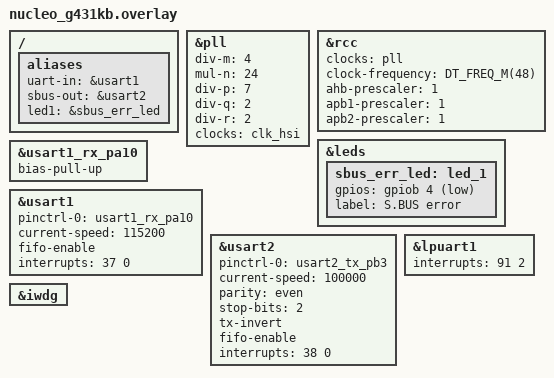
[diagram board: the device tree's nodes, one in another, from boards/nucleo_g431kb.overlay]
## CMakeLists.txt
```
# SPDX-License-Identifier: Apache-2.0

cmake_minimum_required(VERSION 3.28.0)

find_package(Zephyr REQUIRED HINTS $ENV{ZEPHYR_BASE})
project(uart_sbus)

target_sources(app PRIVATE src/main.c src/sbus_pipe.c)
```

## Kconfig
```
# SPDX-License-Identifier: Apache-2.0

mainmenu "UART to S.BUS converter"

source "Kconfig.zephyr"

config UART_SBUS_SBUS2
	bool "Accept S.BUS2 slot footers"
	default n
	help
	  Valid footer iff (byte & mask) == 0x00.
	  n: mask 0xFF (classic S.BUS, footer 0x00 only).
	  y: mask 0xCB (ignore bits 2,4,5: 0x00/0x04/0x14/0x24/0x34).
```

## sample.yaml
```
sample:
  name: UART to S.BUS converter
tests:
  sample.uart_sbus:
    platform_allow:
      - nucleo_g431kb
      - sbus_bridge
    integration_platforms:
      - nucleo_g431kb
      - sbus_bridge
    build_only: true
    tags:
      - uart
      - sbus
```

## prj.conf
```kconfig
CONFIG_SERIAL=y
CONFIG_UART_INTERRUPT_DRIVEN=y
CONFIG_CONSOLE=y
CONFIG_GPIO=y
CONFIG_WATCHDOG=y
CONFIG_RESET_ON_FATAL_ERROR=y
CONFIG_STACK_SENTINEL=y
CONFIG_FAULT_DUMP=1
CONFIG_ISR_STACK_SIZE=1024
CONFIG_MAIN_STACK_SIZE=1024
```

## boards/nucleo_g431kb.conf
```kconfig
CONFIG_UART_CONSOLE=y
# Board defconfig enables MPU stack guards; prefer software sentinel (prj.conf).
CONFIG_HW_STACK_PROTECTION=n
```

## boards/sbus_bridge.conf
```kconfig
# SPDX-License-Identifier: MIT

CONFIG_RTT_CONSOLE=y
CONFIG_USE_SEGGER_RTT=y
```

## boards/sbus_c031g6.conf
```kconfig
# SPDX-License-Identifier: Apache-2.0

# prj.conf enables UART_CONSOLE; this board has no spare USART for VCP.
CONFIG_UART_CONSOLE=n
CONFIG_RTT_CONSOLE=y
CONFIG_USE_SEGGER_RTT=y
```

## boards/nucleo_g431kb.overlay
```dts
/*
 * SPDX-License-Identifier: Apache-2.0
 *
 * NUCLEO-G431KB (UM2397) Arduino Nano mapping, not Nucleo-64:
 *   ST-Link VCP is LPUART1 PA2/PA3 (not D0/D1).
 *   UART in:  USART1 RX PA10 = D0 (CN4 pin 2).
 *   S.BUS:    USART2 TX PB3  = D13 (CN3 pin 15).
 *   Error LED: GPIOB 4 = D12 (CN4 pin 15), open-drain active-low to 5 V.
 * D7 is PF0 (OSC_IN) and D3 is PB0; neither is a USART pin.
 * Default SB2 routes PB7 to A4, not to D4, so USART1_RX_PB7 is a trap.
 * Do not use A7 (PA2): LPUART1 TX / ST-Link VCP, not 5 V-tolerant.
 */

#include <zephyr/dt-bindings/gpio/gpio.h>

/ {
	aliases {
		uart-in = &usart1;
		sbus-out = &usart2;
		led1 = &sbus_err_led;
	};
};

/*
 * Match sbus_bridge (STM32C031) at 48 MHz SYSCLK.
 * G4 HSI is 16 MHz, so PLL is required: 16/4*24/2 = 48.
 */
&pll {
	div-m = <4>;
	mul-n = <24>;
	div-p = <7>;
	div-q = <2>;
	div-r = <2>;
	clocks = <&clk_hsi>;
	status = "okay";
};

&rcc {
	clocks = <&pll>;
	clock-frequency = <DT_FREQ_M(48)>;
	ahb-prescaler = <1>;
	apb1-prescaler = <1>;
	apb2-prescaler = <1>;
};

&leds {
	sbus_err_led: led_1 {
		gpios = <&gpiob 4 (GPIO_OPEN_DRAIN | GPIO_ACTIVE_LOW)>;
		label = "S.BUS error";
	};
};

&usart1_rx_pa10 {
	bias-pull-up;
};

&usart1 {
	pinctrl-0 = <&usart1_rx_pa10>;
	pinctrl-names = "default";
	current-speed = <115200>;
	fifo-enable;
	interrupts = <37 0>;
	status = "okay";
};

&usart2 {
	pinctrl-0 = <&usart2_tx_pb3>;
	pinctrl-names = "default";
	current-speed = <100000>;
	parity = "even";
	stop-bits = "2";
	tx-invert;
	fifo-enable;
	interrupts = <38 0>;
	status = "okay";
};

&lpuart1 {
	interrupts = <91 2>;
};

&iwdg {
	status = "okay";
};
```

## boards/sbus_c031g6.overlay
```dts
/*
 * SPDX-License-Identifier: Apache-2.0
 *
 * Aliases, LEDs, and USART line coding live in the sbus_c031g6 board DTS.
 * This overlay is kept so the sample has an explicit board file; the
 * duplicate aliases match the board and are harmless.
 */

/ {
	aliases {
		uart-in = &usart1;
		sbus-out = &usart2;
		led0 = &led_green;
		led1 = &led_red;
	};
};
```

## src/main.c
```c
/*
 * SPDX-License-Identifier: Apache-2.0
 */

#include <zephyr/device.h>
#include <zephyr/drivers/gpio.h>
#include <zephyr/drivers/uart.h>
#include <zephyr/drivers/watchdog.h>
#include <zephyr/kernel.h>
#include <zephyr/sys/atomic.h>
#include <zephyr/sys/clock.h>
#include <zephyr/sys/printk.h>
#include <zephyr/sys/util.h>

#include "sbus_pipe.h"

#define UART_IN_NODE     DT_ALIAS(uart_in)
#define SBUS_OUT_NODE    DT_ALIAS(sbus_out)
#define LED_GREEN_NODE   DT_ALIAS(led0)
#define LED_RED_NODE     DT_ALIAS(led1)
#define WDT_NODE         DT_ALIAS(watchdog0)

#define MAIN_TICK_MS       5
#define WDT_WINDOW_MS      50
#define GREEN_PULSE_MS     50
#define RED_SUPERSEDE_MS   200
#define RED_FAULT_MS       2000
#define STATS_PERIOD_MS    1000
#define FRAME_LED_DIVISOR  10

BUILD_ASSERT(DT_NODE_EXISTS(UART_IN_NODE), "alias uart-in missing");
BUILD_ASSERT(DT_NODE_EXISTS(SBUS_OUT_NODE), "alias sbus-out missing");
BUILD_ASSERT(DT_NODE_EXISTS(LED_GREEN_NODE), "alias led0 missing");
BUILD_ASSERT(DT_NODE_EXISTS(LED_RED_NODE), "alias led1 missing");
BUILD_ASSERT(DT_NODE_EXISTS(WDT_NODE), "alias watchdog0 missing");
BUILD_ASSERT(DT_IRQ(UART_IN_NODE, priority) == DT_IRQ(SBUS_OUT_NODE, priority),
	     "uart-in and sbus-out must share NVIC priority");

static const struct device *const uart_in = DEVICE_DT_GET(UART_IN_NODE);
static const struct device *const sbus_out = DEVICE_DT_GET(SBUS_OUT_NODE);
static const struct device *const wdt = DEVICE_DT_GET(WDT_NODE);
static const struct gpio_dt_spec led_green = GPIO_DT_SPEC_GET(LED_GREEN_NODE, gpios);
static const struct gpio_dt_spec led_red = GPIO_DT_SPEC_GET(LED_RED_NODE, gpios);

static struct sbus_pipe pipe;
K_SEM_DEFINE(wake, 0, 1);

static void uart_in_cb(const struct device *dev, void *user_data)
{
	uint8_t c;
	int err;

	ARG_UNUSED(user_data);

	uart_irq_update(dev);

	err = uart_err_check(dev);
	if (err != 0) {
		atomic_inc(&pipe.rx_err);
		k_sem_give(&wake);
	}

	while (uart_irq_rx_ready(dev) > 0) {
		if (uart_fifo_read(dev, &c, 1) < 1) {
			break;
		}
		if (sbus_pipe_push(&pipe, c)) {
			uart_irq_tx_enable(sbus_out);
			if (pipe.collect == NULL) {
				k_sem_give(&wake);
			}
		}
	}
}

static void sbus_out_cb(const struct device *dev, void *user_data)
{
	uint8_t c;

	ARG_UNUSED(user_data);

	uart_irq_update(dev);

	while (uart_irq_tx_ready(dev) > 0) {
		if (!sbus_pipe_pop(&pipe, &c)) {
			uart_irq_tx_disable(dev);
			break;
		}
		k_sem_give(&wake);
		if (uart_fifo_fill(dev, &c, 1) < 1) {
			uart_irq_tx_disable(dev);
			break;
		}
	}
}

static uint16_t remaining_sub(uint16_t remaining, uint16_t dt)
{
	return remaining > dt ? remaining - dt : 0;
}

int main(void)
{
	uint32_t tx_frames_prev = 0;
	uint32_t tx_frames_snap = 0;
	uint32_t supersede_snap = 0;
	uint32_t sync_err_snap = 0;
	uint32_t rx_err_snap = 0;
	uint16_t green_ms = 0;
	uint16_t red_ms = 0;
	int64_t last_led = k_uptime_get();
	int64_t last_stats = last_led;
	int wdt_channel;
	struct wdt_timeout_cfg wdt_cfg = {
		.flags = WDT_FLAG_RESET_SOC,
		.window.min = 0,
		.window.max = WDT_WINDOW_MS,
	};

	sbus_pipe_init(&pipe);

	if (!device_is_ready(uart_in) || !device_is_ready(sbus_out)) {
		printk("sbus: UART device not ready\n");
		return 0;
	}
	if (!gpio_is_ready_dt(&led_green) || !gpio_is_ready_dt(&led_red)) {
		printk("sbus: LED GPIO not ready\n");
		return 0;
	}
	if (gpio_pin_configure_dt(&led_green, GPIO_OUTPUT_INACTIVE) < 0 ||
	    gpio_pin_configure_dt(&led_red, GPIO_OUTPUT_INACTIVE) < 0) {
		printk("sbus: LED configure failed\n");
		return 0;
	}
	if (!device_is_ready(wdt)) {
		printk("sbus: watchdog not ready\n");
		return 0;
	}
	wdt_channel = wdt_install_timeout(wdt, &wdt_cfg);
	if (wdt_channel < 0) {
		printk("sbus: watchdog install failed\n");
		return 0;
	}
	if (wdt_setup(wdt, WDT_OPT_PAUSE_HALTED_BY_DBG) < 0) {
		printk("sbus: watchdog setup failed\n");
		return 0;
	}

	uart_irq_callback_user_data_set(uart_in, uart_in_cb, NULL);
	uart_irq_callback_user_data_set(sbus_out, sbus_out_cb, NULL);
	uart_irq_err_enable(uart_in);
	uart_irq_rx_enable(uart_in);

#if defined(CONFIG_BOARD_SBUS_BRIDGE)
	printk("sbus: PA1 115200 8N1 -> PA4 S.BUS 100k 8E2\n");
#elif defined(CONFIG_BOARD_NUCLEO_G431KB)
	printk("sbus: D0/PA10 115200 8N1 -> D13/PB3 S.BUS 100k 8E2\n");
#else
	printk("sbus: 115200 8N1 -> S.BUS 100k 8E2\n");
#endif

	for (;;) {
		int64_t now;
		uint16_t dt;
		uint32_t rx;
		uint32_t tx;
		uint32_t err;
		uint32_t frames;
		uint32_t sup;
		uint32_t sync;
		uint32_t tx_frames;

		k_sem_take(&wake, K_MSEC(MAIN_TICK_MS));
		wdt_feed(wdt, wdt_channel);
		now = k_uptime_get();
		dt = (uint16_t)CLAMP(now - last_led, 0, 1000);
		last_led = now;

		green_ms = remaining_sub(green_ms, dt);
		red_ms = remaining_sub(red_ms, dt);

		tx_frames = (uint32_t)atomic_get(&pipe.tx_frames);
		if ((tx_frames / FRAME_LED_DIVISOR) != (tx_frames_snap / FRAME_LED_DIVISOR)) {
			green_ms = MAX(green_ms, GREEN_PULSE_MS);
		}
		tx_frames_snap = tx_frames;

		sup = (uint32_t)atomic_get(&pipe.supersede);
		if (sup != supersede_snap) {
			red_ms = MAX(red_ms, RED_SUPERSEDE_MS);
		}
		supersede_snap = sup;

		sync = (uint32_t)atomic_get(&pipe.sync_err);
		err = (uint32_t)atomic_get(&pipe.rx_err);
		if (sync != sync_err_snap || err != rx_err_snap) {
			red_ms = MAX(red_ms, RED_FAULT_MS);
		}
		sync_err_snap = sync;
		rx_err_snap = err;

		if (green_ms > 0) {
			gpio_pin_set_dt(&led_green, 1);
		} else {
			gpio_pin_set_dt(&led_green, 0);
		}
		if (red_ms > 0) {
			gpio_pin_set_dt(&led_red, 1);
		} else {
			gpio_pin_set_dt(&led_red, 0);
		}

		if ((now - last_stats) >= STATS_PERIOD_MS) {
			uint32_t fps;

			rx = (uint32_t)atomic_get(&pipe.rx_bytes);
			tx = (uint32_t)atomic_get(&pipe.tx_bytes);
			frames = tx_frames;
			fps = (tx_frames - tx_frames_prev) * MSEC_PER_SEC / (now - last_stats);
			tx_frames_prev = tx_frames;
			last_stats = now;
			printk("sbus: rx=%u tx=%u err=%u frames=%u fps=%u sup=%u sync=%u\n",
			       rx, tx, err, frames, fps, sup, sync);
		}
	}
}
```

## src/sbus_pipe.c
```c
/*
 * SPDX-License-Identifier: Apache-2.0
 */

#include "sbus_pipe.h"

static void sbus_slot_reset(struct sbus_slot *s)
{
	s->len = 0;
	s->rd = 0;
	s->complete = false;
	s->tx_started = false;
}

static bool sbus_slot_owes_tx(const struct sbus_slot *s)
{
	return s->complete || s->tx_started || (s->rd < s->len);
}

static bool sbus_footer_ok(uint8_t footer)
{
	return (footer & SBUS_FOOTER_MASK) == SBUS_FTR;
}

static bool sbus_collecting_current(const struct sbus_pipe *p)
{
	return p->collect == p->current;
}

static bool sbus_current_drained(const struct sbus_pipe *p)
{
	if (sbus_collecting_current(p)) {
		return false;
	}
	if (p->current->len == 0 && !p->current->tx_started && !p->current->complete) {
		return false;
	}
	return p->current->rd == p->current->len;
}

static void sbus_swap_slots(struct sbus_slot **a, struct sbus_slot **b)
{
	struct sbus_slot *tmp = *a;

	*a = *b;
	*b = tmp;
}

static void sbus_commit_scratch(struct sbus_pipe *p)
{
	if (p->next->complete) {
		atomic_inc(&p->supersede);
	}
	sbus_swap_slots(&p->next, &p->scratch);
	sbus_slot_reset(p->scratch);
}

static void sbus_promote(struct sbus_pipe *p)
{
	sbus_swap_slots(&p->current, &p->next);
	sbus_slot_reset(p->next);
}

void sbus_pipe_init(struct sbus_pipe *p)
{
	sbus_slot_reset(&p->slots[0]);
	sbus_slot_reset(&p->slots[1]);
	sbus_slot_reset(&p->slots[2]);
	p->current = &p->slots[0];
	p->next = &p->slots[1];
	p->scratch = &p->slots[2];
	p->collect = NULL;
	atomic_set(&p->rx_bytes, 0);
	atomic_set(&p->tx_bytes, 0);
	atomic_set(&p->rx_err, 0);
	atomic_set(&p->rx_frames, 0);
	atomic_set(&p->tx_frames, 0);
	atomic_set(&p->supersede, 0);
	atomic_set(&p->sync_err, 0);
}

bool sbus_pipe_push(struct sbus_pipe *p, uint8_t b)
{
	if (p->collect == NULL) {
		if (b != SBUS_HDR) {
			return false;
		}
		if (!sbus_slot_owes_tx(p->current)) {
			p->collect = p->current;
		} else if (!p->next->complete) {
			p->collect = p->next;
		} else {
			p->collect = p->scratch;
		}
	}

	p->collect->buf[p->collect->len] = b;
	p->collect->len++;
	atomic_inc(&p->rx_bytes);

	if (p->collect->len < SBUS_FRAME_LEN) {
		return true;
	}

	if (sbus_footer_ok(p->collect->buf[SBUS_FRAME_LEN - 1])) {
		p->collect->complete = true;
		if (p->collect == p->scratch) {
			sbus_commit_scratch(p);
		}
		atomic_inc(&p->rx_frames);
	} else {
		atomic_inc(&p->sync_err);
		if (p->collect != p->current) {
			sbus_slot_reset(p->collect);
		}
	}

	p->collect = NULL;
	return true;
}

bool sbus_pipe_pop(struct sbus_pipe *p, uint8_t *b)
{
	if (p->current->rd >= p->current->len) {
		return false;
	}

	*b = p->current->buf[p->current->rd];
	p->current->rd++;
	p->current->tx_started = true;
	atomic_inc(&p->tx_bytes);

	if (sbus_current_drained(p)) {
		if (p->current->complete) {
			atomic_inc(&p->tx_frames);
		}
		sbus_promote(p);
	}

	return true;
}

bool sbus_pipe_is_empty(const struct sbus_pipe *p)
{
	return p->current->rd == p->current->len;
}
```

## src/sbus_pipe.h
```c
/*
 * SPDX-License-Identifier: Apache-2.0
 */

#ifndef SBUS_PIPE_H_
#define SBUS_PIPE_H_

#include <stdbool.h>
#include <stdint.h>

#include <zephyr/sys/atomic.h>
#include <zephyr/sys/util.h>

#define SBUS_FRAME_LEN 25
#define SBUS_HDR       0x0F
#define SBUS_FTR       0x00
/* Off: 0xFF (exact 0x00). On: 0xCB, ignore Futaba slot bits 2,4,5. */
#define SBUS_FOOTER_MASK (IS_ENABLED(CONFIG_UART_SBUS_SBUS2) ? 0xCBu : 0xFFu)

struct sbus_slot {
	uint8_t buf[SBUS_FRAME_LEN];
	uint8_t len;       /* bytes valid (RX write index / TX owed) */
	uint8_t rd;        /* TX read index */
	bool complete;     /* len==25 and footer passed the mask */
	bool tx_started;   /* at least one byte given to USART FIFO */
};

struct sbus_pipe {
	struct sbus_slot slots[3];
	struct sbus_slot *current; /* TX drains this */
	struct sbus_slot *next;    /* successor: partial collect, complete, or empty */
	struct sbus_slot *scratch; /* COLLECT dest when next is already complete */
	struct sbus_slot *collect; /* COLLECT dest; NULL while hunting */

	atomic_t rx_bytes;
	atomic_t tx_bytes;
	atomic_t rx_err;
	atomic_t rx_frames;
	atomic_t tx_frames;
	atomic_t supersede;
	atomic_t sync_err;
};

/**
 * @brief Initialize an S.BUS three-slot assembler.
 *
 * Resets all three frame slots, points current/next/scratch at slots
 * 0/1/2, enters hunt, and zeroes all statistics counters.
 *
 * @param p Pipe instance.
 */
void sbus_pipe_init(struct sbus_pipe *p);

/**
 * @brief Feed one UART RX byte into the assembler.
 *
 * While hunting, non-header bytes are discarded and do not increment
 * @c sync_err. A header (@c SBUS_HDR) starts a locked 25-byte collect
 * window; interior @c 0x0F is payload, not a resync.
 *
 * Bytes are cut through into current when that slot owes no TX.
 * Otherwise they assemble into next when next is not complete, or into
 * scratch when next already holds a complete waiting frame. A valid
 * footer commits the frame (@c rx_frames). A completed scratch is
 * pointer-swapped with next; if next was already complete, the waiting
 * frame is dropped (@c supersede). A bad footer increments @c sync_err;
 * in-flight cut-through bytes on current are left for TX, while an
 * incomplete next or scratch is reset.
 *
 * Increments @c rx_bytes for every accepted collect byte, including the
 * header.
 *
 * @param p Pipe instance.
 * @param b Received byte.
 *
 * @retval true  Byte was accepted into a collect window.
 * @retval false Byte was ignored while hunting.
 */
bool sbus_pipe_push(struct sbus_pipe *p, uint8_t b);

/**
 * @brief Pop the next byte owed to S.BUS TX.
 *
 * Copies the next unread byte from current and advances the read index.
 * The first successful pop on a slot sets @c tx_started. When current
 * is drained (read has caught write, and RX is not still collecting
 * into it), @c tx_frames is incremented if the slot was complete, then
 * the pipe promotes next to current.
 *
 * An idle empty slot is not promoted. A drained incomplete cut-through
 * (bad footer) is promoted so the pipe cannot stall.
 *
 * @param p Pipe instance.
 * @param[out] b Destination for the popped byte. Written only on success.
 *
 * @retval true  A byte was written to @p b.
 * @retval false Nothing is owed to TX on current.
 */
bool sbus_pipe_pop(struct sbus_pipe *p, uint8_t *b);

/**
 * @brief Check whether TX has caught up on the current slot.
 *
 * True when current's read index equals its length. During cut-through,
 * that is also true between RX bytes (TX's view of a gap).
 *
 * @param p Pipe instance.
 *
 * @retval true  No bytes remain to pop from current.
 * @retval false At least one byte is still owed to TX.
 */
bool sbus_pipe_is_empty(const struct sbus_pipe *p);

#endif /* SBUS_PIPE_H_ */
```
